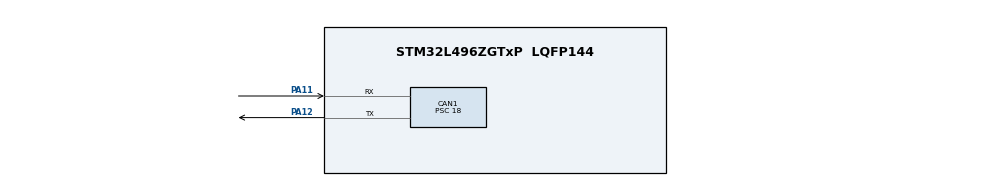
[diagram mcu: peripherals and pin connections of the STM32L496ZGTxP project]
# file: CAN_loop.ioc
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CAN1.BS1=CAN_BS1_2TQ
CAN1.CalculateBaudRate=55555
CAN1.CalculateTimeBit=18000
CAN1.CalculateTimeQuantum=4500.0
CAN1.Mode=CAN_MODE_LOOPBACK
CAN1.Prescaler=18
Mcu.Family=STM32L4
Mcu.Name=STM32L496ZGTxP
Mcu.Package=LQFP144
NVIC.CAN1_RX0_IRQn=true\:0\:0\:false\:false\:true\:true\:true\:true
NVIC.CAN1_RX1_IRQn=true\:0\:0\:false\:false\:true\:true\:true\:true
NVIC.PriorityGroup=NVIC_PRIORITYGROUP_4
PA11.Mode=CAN_Activate
PA11.Signal=CAN1_RX
PA12.Mode=CAN_Activate
PA12.Signal=CAN1_TX
PA13\ (JTMS/SWDIO).Mode=Serial_Wire
PA13\ (JTMS/SWDIO).Signal=SYS_JTMS-SWDIO
PA14\ (JTCK/SWCLK).Mode=Serial_Wire
PA14\ (JTCK/SWCLK).Signal=SYS_JTCK-SWCLK
PH0-OSC_IN\ (PH0).Mode=HSE-External-Oscillator
PH0-OSC_IN\ (PH0).Signal=RCC_OSC_IN
PH1-OSC_OUT\ (PH1).Mode=HSE-External-Oscillator
PH1-OSC_OUT\ (PH1).Signal=RCC_OSC_OUT
ProjectManager.HeapSize=0x200
ProjectManager.StackSize=0x400
ProjectManager.TargetToolchain=STM32CubeIDE
RCC.HSE_VALUE=8000000
RCC.HSI48_VALUE=48000000
RCC.HSI_VALUE=16000000
RCC.LSE_VALUE=32768
RCC.MSI_VALUE=4000000
RCC.VCOOutputFreq_Value=32000000
board=custom

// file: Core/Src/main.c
/* USER CODE BEGIN Header */
/**
  ******************************************************************************
  * @file           : main.c
  * @brief          : Main program body
  ******************************************************************************
  * @attention
  *
  * Copyright (c) 2023 STMicroelectronics.
  * All rights reserved.
  *
  * This software is licensed under terms that can be found in the LICENSE file
  * in the root directory of this software component.
  * If no LICENSE file comes with this software, it is provided AS-IS.
  *
  ******************************************************************************
  */
/* USER CODE END Header */
#include "main.h"

CAN_HandleTypeDef hcan1;

void SystemClock_Config(void);
static void MX_GPIO_Init(void);
static void MX_CAN1_Init(void);

/* USER CODE BEGIN 0 */

CAN_TxHeaderTypeDef TxHeader;
CAN_RxHeaderTypeDef RxHeader;
uint32_t txmailbox;
uint8_t txdata[8];
uint8_t rxdata[8];

uint8_t count = 0;

void HAL_CAN_RxFifo0MsgPendingCallback(CAN_HandleTypeDef *hcan)
{
	HAL_CAN_GetRxMessage(hcan, CAN_RX_FIFO0, &RxHeader, rxdata);
	count++;
}
/* USER CODE END 0 */

int main(void)
{

  /* MCU Configuration--------------------------------------------------------*/

  /* Reset of all peripherals, Initializes the Flash interface and the Systick. */
  HAL_Init();

  /* Configure the system clock */
  SystemClock_Config();

  /* Initialize all configured peripherals */
  MX_GPIO_Init();
  MX_CAN1_Init();
  /* USER CODE BEGIN 2 */

  HAL_CAN_Start(&hcan1);
  HAL_CAN_ActivateNotification(&hcan1, CAN_IT_RX_FIFO0_MSG_PENDING);

  TxHeader.DLC=1;
  TxHeader.ExtId=0;
  TxHeader.IDE= CAN_ID_STD;
  TxHeader.RTR= CAN_RTR_DATA;
  TxHeader.StdId= 0x111;
  TxHeader.TransmitGlobalTime= DISABLE;
  txdata[0]=0x05;

  /* USER CODE END 2 */

  /* Infinite loop */
  while (1)
  {
	  HAL_CAN_AddTxMessage(&hcan1, &TxHeader, txdata, &txmailbox); // Transmit data
	      HAL_Delay(1000); // Delay for 1 second
  }
}

void SystemClock_Config(void)
{
  RCC_OscInitTypeDef RCC_OscInitStruct = {0};
  RCC_ClkInitTypeDef RCC_ClkInitStruct = {0};

  /** Configure the main internal regulator output voltage
  */
  if (HAL_PWREx_ControlVoltageScaling(PWR_REGULATOR_VOLTAGE_SCALE1) != HAL_OK)
  {
    Error_Handler();
  }

  /** Initializes the RCC Oscillators according to the specified parameters
  * in the RCC_OscInitTypeDef structure.
  */
  RCC_OscInitStruct.OscillatorType = RCC_OSCILLATORTYPE_MSI;
  RCC_OscInitStruct.MSIState = RCC_MSI_ON;
  RCC_OscInitStruct.MSICalibrationValue = 0;
  RCC_OscInitStruct.MSIClockRange = RCC_MSIRANGE_6;
  RCC_OscInitStruct.PLL.PLLState = RCC_PLL_NONE;
  if (HAL_RCC_OscConfig(&RCC_OscInitStruct) != HAL_OK)
  {
    Error_Handler();
  }

  /** Initializes the CPU, AHB and APB buses clocks
  */
  RCC_ClkInitStruct.ClockType = RCC_CLOCKTYPE_HCLK|RCC_CLOCKTYPE_SYSCLK
                              |RCC_CLOCKTYPE_PCLK1|RCC_CLOCKTYPE_PCLK2;
  RCC_ClkInitStruct.SYSCLKSource = RCC_SYSCLKSOURCE_MSI;
  RCC_ClkInitStruct.AHBCLKDivider = RCC_SYSCLK_DIV1;
  RCC_ClkInitStruct.APB1CLKDivider = RCC_HCLK_DIV1;
  RCC_ClkInitStruct.APB2CLKDivider = RCC_HCLK_DIV1;

  if (HAL_RCC_ClockConfig(&RCC_ClkInitStruct, FLASH_LATENCY_0) != HAL_OK)
  {
    Error_Handler();
  }
}

static void MX_CAN1_Init(void)
{

  hcan1.Instance = CAN1;
  hcan1.Init.Prescaler = 18;
  hcan1.Init.Mode = CAN_MODE_LOOPBACK;
  hcan1.Init.SyncJumpWidth = CAN_SJW_1TQ;
  hcan1.Init.TimeSeg1 = CAN_BS1_2TQ;
  hcan1.Init.TimeSeg2 = CAN_BS2_1TQ;
  hcan1.Init.TimeTriggeredMode = DISABLE;
  hcan1.Init.AutoBusOff = DISABLE;
  hcan1.Init.AutoWakeUp = DISABLE;
  hcan1.Init.AutoRetransmission = DISABLE;
  hcan1.Init.ReceiveFifoLocked = DISABLE;
  hcan1.Init.TransmitFifoPriority = DISABLE;
  if (HAL_CAN_Init(&hcan1) != HAL_OK)
  {
    Error_Handler();
  }
  /* USER CODE BEGIN CAN1_Init 2 */
  CAN_FilterTypeDef canfilterconfig;

  canfilterconfig.FilterActivation = CAN_FILTER_ENABLE;
    canfilterconfig.FilterBank = 10;  // anything between 0 to SlaveStartFilterBank
    canfilterconfig.FilterFIFOAssignment = CAN_RX_FIFO0;
    canfilterconfig.FilterIdHigh = 0x103<<5;
    canfilterconfig.FilterIdLow = 0x0000;
    canfilterconfig.FilterMaskIdHigh = 0x1<<13;
    canfilterconfig.FilterMaskIdLow = 0x0000;
    canfilterconfig.FilterMode = CAN_FILTERMODE_IDMASK;
    canfilterconfig.FilterScale = CAN_FILTERSCALE_32BIT;
    canfilterconfig.SlaveStartFilterBank = 13;  // 13 to 27 are assigned to slave CAN (CAN 2) OR 0 to 12 are assgned to CAN1

  HAL_CAN_ConfigFilter(&hcan1, &canfilterconfig);
  /* USER CODE END CAN1_Init 2 */

}

static void MX_GPIO_Init(void)
{

  /* GPIO Ports Clock Enable */
  __HAL_RCC_GPIOH_CLK_ENABLE();
  __HAL_RCC_GPIOA_CLK_ENABLE();

}

void Error_Handler(void)
{
  __disable_irq();
  while (1)
  {
  }
}
